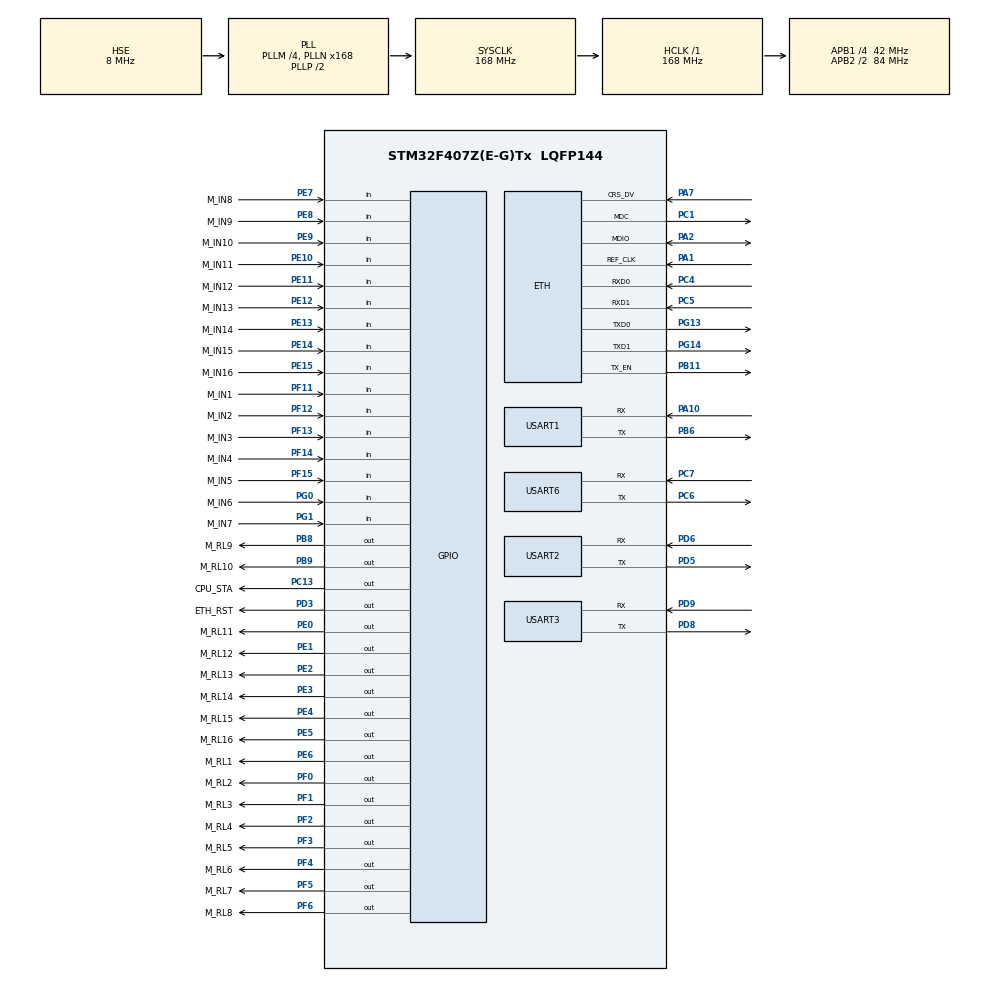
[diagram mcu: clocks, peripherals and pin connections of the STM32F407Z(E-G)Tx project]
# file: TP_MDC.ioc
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Dma.Request0=USART1_RX
Dma.Request1=USART1_TX
Dma.Request2=USART2_RX
Dma.Request3=USART2_TX
Dma.Request4=USART3_RX
Dma.Request5=USART3_TX
Dma.Request6=USART6_RX
Dma.Request7=USART6_TX
Dma.USART1_RX.0.Direction=DMA_PERIPH_TO_MEMORY
Dma.USART1_RX.0.FIFOMode=DMA_FIFOMODE_DISABLE
Dma.USART1_RX.0.Instance=DMA2_Stream2
Dma.USART1_RX.0.MemDataAlignment=DMA_MDATAALIGN_BYTE
Dma.USART1_RX.0.MemInc=DMA_MINC_ENABLE
Dma.USART1_RX.0.Mode=DMA_CIRCULAR
Dma.USART1_RX.0.PeriphDataAlignment=DMA_PDATAALIGN_BYTE
Dma.USART1_RX.0.PeriphInc=DMA_PINC_DISABLE
Dma.USART1_RX.0.Priority=DMA_PRIORITY_LOW
Dma.USART1_TX.1.Direction=DMA_MEMORY_TO_PERIPH
Dma.USART1_TX.1.FIFOMode=DMA_FIFOMODE_DISABLE
Dma.USART1_TX.1.Instance=DMA2_Stream7
Dma.USART1_TX.1.MemDataAlignment=DMA_MDATAALIGN_BYTE
Dma.USART1_TX.1.MemInc=DMA_MINC_ENABLE
Dma.USART1_TX.1.Mode=DMA_NORMAL
Dma.USART1_TX.1.PeriphDataAlignment=DMA_PDATAALIGN_BYTE
Dma.USART1_TX.1.PeriphInc=DMA_PINC_DISABLE
Dma.USART1_TX.1.Priority=DMA_PRIORITY_LOW
Dma.USART2_RX.2.Direction=DMA_PERIPH_TO_MEMORY
Dma.USART2_RX.2.FIFOMode=DMA_FIFOMODE_DISABLE
Dma.USART2_RX.2.Instance=DMA1_Stream5
Dma.USART2_RX.2.MemDataAlignment=DMA_MDATAALIGN_BYTE
Dma.USART2_RX.2.MemInc=DMA_MINC_ENABLE
Dma.USART2_RX.2.Mode=DMA_CIRCULAR
Dma.USART2_RX.2.PeriphDataAlignment=DMA_PDATAALIGN_BYTE
Dma.USART2_RX.2.PeriphInc=DMA_PINC_DISABLE
Dma.USART2_RX.2.Priority=DMA_PRIORITY_LOW
Dma.USART2_TX.3.Direction=DMA_MEMORY_TO_PERIPH
Dma.USART2_TX.3.FIFOMode=DMA_FIFOMODE_DISABLE
Dma.USART2_TX.3.Instance=DMA1_Stream6
Dma.USART2_TX.3.MemDataAlignment=DMA_MDATAALIGN_BYTE
Dma.USART2_TX.3.MemInc=DMA_MINC_ENABLE
Dma.USART2_TX.3.Mode=DMA_NORMAL
Dma.USART2_TX.3.PeriphDataAlignment=DMA_PDATAALIGN_BYTE
Dma.USART2_TX.3.PeriphInc=DMA_PINC_DISABLE
Dma.USART2_TX.3.Priority=DMA_PRIORITY_LOW
Dma.USART3_RX.4.Direction=DMA_PERIPH_TO_MEMORY
Dma.USART3_RX.4.FIFOMode=DMA_FIFOMODE_DISABLE
Dma.USART3_RX.4.Instance=DMA1_Stream1
Dma.USART3_RX.4.MemDataAlignment=DMA_MDATAALIGN_BYTE
Dma.USART3_RX.4.MemInc=DMA_MINC_ENABLE
Dma.USART3_RX.4.Mode=DMA_CIRCULAR
Dma.USART3_RX.4.PeriphDataAlignment=DMA_PDATAALIGN_BYTE
Dma.USART3_RX.4.PeriphInc=DMA_PINC_DISABLE
Dma.USART3_RX.4.Priority=DMA_PRIORITY_LOW
Dma.USART3_TX.5.Direction=DMA_MEMORY_TO_PERIPH
Dma.USART3_TX.5.FIFOMode=DMA_FIFOMODE_DISABLE
Dma.USART3_TX.5.Instance=DMA1_Stream3
Dma.USART3_TX.5.MemDataAlignment=DMA_MDATAALIGN_BYTE
Dma.USART3_TX.5.MemInc=DMA_MINC_ENABLE
Dma.USART3_TX.5.Mode=DMA_NORMAL
Dma.USART3_TX.5.PeriphDataAlignment=DMA_PDATAALIGN_BYTE
Dma.USART3_TX.5.PeriphInc=DMA_PINC_DISABLE
Dma.USART3_TX.5.Priority=DMA_PRIORITY_LOW
Dma.USART6_RX.6.Direction=DMA_PERIPH_TO_MEMORY
Dma.USART6_RX.6.FIFOMode=DMA_FIFOMODE_DISABLE
Dma.USART6_RX.6.Instance=DMA2_Stream1
Dma.USART6_RX.6.MemDataAlignment=DMA_MDATAALIGN_BYTE
Dma.USART6_RX.6.MemInc=DMA_MINC_ENABLE
Dma.USART6_RX.6.Mode=DMA_CIRCULAR
Dma.USART6_RX.6.PeriphDataAlignment=DMA_PDATAALIGN_BYTE
Dma.USART6_RX.6.PeriphInc=DMA_PINC_DISABLE
Dma.USART6_RX.6.Priority=DMA_PRIORITY_LOW
Dma.USART6_TX.7.Direction=DMA_MEMORY_TO_PERIPH
Dma.USART6_TX.7.FIFOMode=DMA_FIFOMODE_DISABLE
Dma.USART6_TX.7.Instance=DMA2_Stream6
Dma.USART6_TX.7.MemDataAlignment=DMA_MDATAALIGN_BYTE
Dma.USART6_TX.7.MemInc=DMA_MINC_ENABLE
Dma.USART6_TX.7.Mode=DMA_NORMAL
Dma.USART6_TX.7.PeriphDataAlignment=DMA_PDATAALIGN_BYTE
Dma.USART6_TX.7.PeriphInc=DMA_PINC_DISABLE
Dma.USART6_TX.7.Priority=DMA_PRIORITY_LOW
ETH.MediaInterface=HAL_ETH_RMII_MODE
FREERTOS.Tasks01=defaultTask,24,512,StartDefaultTask,Default,NULL,Dynamic,NULL,NULL
FREERTOS.configTOTAL_HEAP_SIZE=49152
LWIP.BSP.number=1
LWIP.IP_ADDRESS=192.168.031.100
LWIP.LWIP_DHCP=0
LWIP.NETMASK_ADDRESS=255.255.255.000
LWIP.Version=v2.1.2_Cube
LWIP0.BSP.STBoard=false
LWIP0.BSP.api=BSP_COMPONENT_DRIVER
LWIP0.BSP.component=LAN8742
LWIP0.BSP.instance=LAN8742
LWIP0.BSP.name=Driver_PHY
LWIP0.BSP.semaphore=S_LAN8742
LWIP0.BSP.solution=LAN8742
Mcu.Family=STM32F4
Mcu.Name=STM32F407Z(E-G)Tx
Mcu.Package=LQFP144
NVIC.DMA1_Stream1_IRQn=true\:5\:0\:false\:false\:true\:true\:false\:true\:true
NVIC.DMA1_Stream3_IRQn=true\:5\:0\:false\:false\:true\:true\:false\:true\:true
NVIC.DMA1_Stream5_IRQn=true\:5\:0\:false\:false\:true\:true\:false\:true\:true
NVIC.DMA1_Stream6_IRQn=true\:5\:0\:false\:false\:true\:true\:false\:true\:true
NVIC.DMA2_Stream1_IRQn=true\:5\:0\:false\:false\:true\:true\:false\:true\:true
NVIC.DMA2_Stream2_IRQn=true\:5\:0\:false\:false\:true\:true\:false\:true\:true
NVIC.DMA2_Stream6_IRQn=true\:5\:0\:false\:false\:true\:true\:false\:true\:true
NVIC.DMA2_Stream7_IRQn=true\:5\:0\:false\:false\:true\:true\:false\:true\:true
NVIC.ETH_IRQn=true\:5\:0\:false\:false\:true\:true\:false\:true\:true
NVIC.PriorityGroup=NVIC_PRIORITYGROUP_4
NVIC.TIM2_IRQn=true\:15\:0\:true\:false\:true\:false\:false\:true\:true
NVIC.TimeBase=TIM2_IRQn
NVIC.TimeBaseIP=TIM2
NVIC.USART1_IRQn=true\:5\:0\:false\:false\:true\:true\:true\:true\:true
NVIC.USART2_IRQn=true\:5\:0\:false\:false\:true\:true\:true\:true\:true
NVIC.USART3_IRQn=true\:5\:0\:false\:false\:true\:true\:true\:true\:true
NVIC.USART6_IRQn=true\:5\:0\:false\:false\:true\:true\:true\:true\:true
PA1.Mode=RMII
PA1.Signal=ETH_REF_CLK
PA10.Mode=Asynchronous
PA10.Signal=USART1_RX
PA13.Mode=Serial_Wire
PA13.Signal=SYS_JTMS-SWDIO
PA14.Mode=Serial_Wire
PA14.Signal=SYS_JTCK-SWCLK
PA2.Mode=RMII
PA2.Signal=ETH_MDIO
PA7.Mode=RMII
PA7.Signal=ETH_CRS_DV
PB11.Mode=RMII
PB11.Signal=ETH_TX_EN
PB6.Mode=Asynchronous
PB6.Signal=USART1_TX
PB8.GPIO_Label=M_RL9
PB8.GPIO_PuPd=GPIO_PULLDOWN
PB8.GPIO_Speed=GPIO_SPEED_FREQ_MEDIUM
PB8.PinState=GPIO_PIN_RESET
PB8.Signal=GPIO_Output
PB9.GPIO_Label=M_RL10
PB9.GPIO_PuPd=GPIO_PULLDOWN
PB9.GPIO_Speed=GPIO_SPEED_FREQ_MEDIUM
PB9.Signal=GPIO_Output
PC1.Mode=RMII
PC1.Signal=ETH_MDC
PC13-ANTI_TAMP.GPIO_Label=CPU_STA
PC13-ANTI_TAMP.Signal=GPIO_Output
PC14-OSC32_IN.Mode=LSE-External-Oscillator
PC14-OSC32_IN.Signal=RCC_OSC32_IN
PC15-OSC32_OUT.Mode=LSE-External-Oscillator
PC15-OSC32_OUT.Signal=RCC_OSC32_OUT
PC4.Mode=RMII
PC4.Signal=ETH_RXD0
PC5.Mode=RMII
PC5.Signal=ETH_RXD1
PC6.Mode=Asynchronous
PC6.Signal=USART6_TX
PC7.Mode=Asynchronous
PC7.Signal=USART6_RX
PD3.GPIO_Label=ETH_RST
PD3.Signal=GPIO_Output
PD5.Mode=Asynchronous
PD5.Signal=USART2_TX
PD6.Mode=Asynchronous
PD6.Signal=USART2_RX
PD8.Mode=Asynchronous
PD8.Signal=USART3_TX
PD9.Mode=Asynchronous
PD9.Signal=USART3_RX
PE0.GPIO_Label=M_RL11
PE0.GPIO_PuPd=GPIO_PULLDOWN
PE0.GPIO_Speed=GPIO_SPEED_FREQ_MEDIUM
PE0.Signal=GPIO_Output
PE1.GPIO_Label=M_RL12
PE1.GPIO_PuPd=GPIO_PULLDOWN
PE1.GPIO_Speed=GPIO_SPEED_FREQ_MEDIUM
PE1.Signal=GPIO_Output
PE10.GPIO_Label=M_IN11
PE10.GPIO_PuPd=GPIO_PULLUP
PE10.Signal=GPIO_Input
PE11.GPIO_Label=M_IN12
PE11.GPIO_PuPd=GPIO_PULLUP
PE11.Signal=GPIO_Input
PE12.GPIO_Label=M_IN13
PE12.GPIO_PuPd=GPIO_PULLUP
PE12.Signal=GPIO_Input
PE13.GPIO_Label=M_IN14
PE13.GPIO_PuPd=GPIO_PULLUP
PE13.Signal=GPIO_Input
PE14.GPIO_Label=M_IN15
PE14.GPIO_PuPd=GPIO_PULLUP
PE14.Signal=GPIO_Input
PE15.GPIO_Label=M_IN16
PE15.GPIO_PuPd=GPIO_PULLUP
PE15.Signal=GPIO_Input
PE2.GPIO_Label=M_RL13
PE2.GPIO_PuPd=GPIO_PULLDOWN
PE2.GPIO_Speed=GPIO_SPEED_FREQ_MEDIUM
PE2.Signal=GPIO_Output
PE3.GPIO_Label=M_RL14
PE3.GPIO_PuPd=GPIO_PULLDOWN
PE3.GPIO_Speed=GPIO_SPEED_FREQ_MEDIUM
PE3.Signal=GPIO_Output
PE4.GPIO_Label=M_RL15
PE4.GPIO_PuPd=GPIO_PULLDOWN
PE4.GPIO_Speed=GPIO_SPEED_FREQ_MEDIUM
PE4.Signal=GPIO_Output
PE5.GPIO_Label=M_RL16
PE5.GPIO_PuPd=GPIO_PULLDOWN
PE5.GPIO_Speed=GPIO_SPEED_FREQ_MEDIUM
PE5.Signal=GPIO_Output
PE6.GPIO_Label=M_RL1
PE6.GPIO_PuPd=GPIO_PULLDOWN
PE6.GPIO_Speed=GPIO_SPEED_FREQ_MEDIUM
PE6.Signal=GPIO_Output
PE7.GPIO_Label=M_IN8
PE7.GPIO_PuPd=GPIO_PULLUP
PE7.Signal=GPIO_Input
PE8.GPIO_Label=M_IN9
PE8.GPIO_PuPd=GPIO_PULLUP
PE8.Signal=GPIO_Input
PE9.GPIO_Label=M_IN10
PE9.GPIO_PuPd=GPIO_PULLUP
PE9.Signal=GPIO_Input
PF0.GPIO_Label=M_RL2
PF0.GPIO_PuPd=GPIO_PULLDOWN
PF0.GPIO_Speed=GPIO_SPEED_FREQ_MEDIUM
PF0.Signal=GPIO_Output
PF1.GPIO_Label=M_RL3
PF1.GPIO_PuPd=GPIO_PULLDOWN
PF1.GPIO_Speed=GPIO_SPEED_FREQ_MEDIUM
PF1.Signal=GPIO_Output
PF11.GPIO_Label=M_IN1
PF11.GPIO_PuPd=GPIO_PULLUP
PF11.Signal=GPIO_Input
PF12.GPIO_Label=M_IN2
PF12.GPIO_PuPd=GPIO_PULLUP
PF12.Signal=GPIO_Input
PF13.GPIO_Label=M_IN3
PF13.GPIO_PuPd=GPIO_PULLUP
PF13.Signal=GPIO_Input
PF14.GPIO_Label=M_IN4
PF14.GPIO_PuPd=GPIO_PULLUP
PF14.Signal=GPIO_Input
PF15.GPIO_Label=M_IN5
PF15.GPIO_PuPd=GPIO_PULLUP
PF15.Signal=GPIO_Input
PF2.GPIO_Label=M_RL4
PF2.GPIO_PuPd=GPIO_PULLDOWN
PF2.GPIO_Speed=GPIO_SPEED_FREQ_MEDIUM
PF2.Signal=GPIO_Output
PF3.GPIO_Label=M_RL5
PF3.GPIO_PuPd=GPIO_PULLDOWN
PF3.GPIO_Speed=GPIO_SPEED_FREQ_MEDIUM
PF3.Signal=GPIO_Output
PF4.GPIO_Label=M_RL6
PF4.GPIO_PuPd=GPIO_PULLDOWN
PF4.GPIO_Speed=GPIO_SPEED_FREQ_MEDIUM
PF4.Signal=GPIO_Output
PF5.GPIO_Label=M_RL7
PF5.GPIO_PuPd=GPIO_PULLDOWN
PF5.GPIO_Speed=GPIO_SPEED_FREQ_MEDIUM
PF5.Signal=GPIO_Output
PF6.GPIO_Label=M_RL8
PF6.GPIO_PuPd=GPIO_PULLDOWN
PF6.GPIO_Speed=GPIO_SPEED_FREQ_MEDIUM
PF6.Signal=GPIO_Output
PG0.GPIO_Label=M_IN6
PG0.GPIO_PuPd=GPIO_PULLUP
PG0.Signal=GPIO_Input
PG1.GPIO_Label=M_IN7
PG1.GPIO_PuPd=GPIO_PULLUP
PG1.Signal=GPIO_Input
PG13.Mode=RMII
PG13.Signal=ETH_TXD0
PG14.Mode=RMII
PG14.Signal=ETH_TXD1
PH0-OSC_IN.Mode=HSE-External-Oscillator
PH0-OSC_IN.Signal=RCC_OSC_IN
PH1-OSC_OUT.Mode=HSE-External-Oscillator
PH1-OSC_OUT.Signal=RCC_OSC_OUT
ProjectManager.HeapSize=0x2000
ProjectManager.StackSize=0x2000
ProjectManager.TargetToolchain=CMake
RCC.48MHZClocksFreq_Value=48000000
RCC.AHBFreq_Value=168000000
RCC.APB1CLKDivider=RCC_HCLK_DIV4
RCC.APB1Freq_Value=42000000
RCC.APB1TimFreq_Value=84000000
RCC.APB2CLKDivider=RCC_HCLK_DIV2
RCC.APB2Freq_Value=84000000
RCC.APB2TimFreq_Value=168000000
RCC.CortexFreq_Value=168000000
RCC.HCLKFreq_Value=168000000
RCC.HSE_VALUE=8000000
RCC.HSI_VALUE=16000000
RCC.PLLM=4
RCC.PLLN=168
RCC.PLLQ=7
RCC.PLLSourceVirtual=RCC_PLLSOURCE_HSE
RCC.SYSCLKFreq_VALUE=168000000
RCC.SYSCLKSource=RCC_SYSCLKSOURCE_PLLCLK
RCC.VCOOutputFreq_Value=336000000
USART1.VirtualMode=VM_ASYNC
USART2.VirtualMode=VM_ASYNC
USART3.VirtualMode=VM_ASYNC
USART6.VirtualMode=VM_ASYNC
VP_FREERTOS_VS_CMSIS_V2.Mode=CMSIS_V2
VP_IWDG_VS_IWDG.Mode=IWDG_Activate
VP_LWIP_VS_Enabled.Mode=Enabled
VP_SYS_VS_tim2.Mode=TIM2
board=custom

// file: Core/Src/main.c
/* USER CODE BEGIN Header */
/**
  ******************************************************************************
  * @file           : main.c
  * @brief          : Main program body
  ******************************************************************************
  * @attention
  *
  * Copyright (c) 2026 STMicroelectronics.
  * All rights reserved.
  *
  * This software is licensed under terms that can be found in the LICENSE file
  * in the root directory of this software component.
  * If no LICENSE file comes with this software, it is provided AS-IS.
  *
  ******************************************************************************
  */
/* USER CODE END Header */
#include "main.h"
#include "cmsis_os.h"
#include "dma.h"
#include "lwip.h"
#include "usart.h"
#include "gpio.h"

/* USER CODE BEGIN Includes */
#include "app_main.h"
/* USER CODE END Includes */

void SystemClock_Config(void);
void MX_FREERTOS_Init(void);

int main(void)
{

  /* MCU Configuration--------------------------------------------------------*/

  /* Reset of all peripherals, Initializes the Flash interface and the Systick. */
  HAL_Init();

  /* Configure the system clock */
  SystemClock_Config();

  /* Initialize all configured peripherals */
  MX_GPIO_Init();
  MX_DMA_Init();
  MX_USART1_UART_Init();
  MX_USART2_UART_Init();
  MX_USART3_UART_Init();
  MX_USART6_UART_Init();
  /* USER CODE BEGIN 2 */
  // App_Init();
  /* USER CODE END 2 */

  /* Init scheduler */
  osKernelInitialize();  /* Call init function for freertos objects (in cmsis_os2.c) */
  MX_FREERTOS_Init();

  /* Start scheduler */
  osKernelStart();

  /* We should never get here as control is now taken by the scheduler */

  /* Infinite loop */
  while (1)
  {

  }
}

void SystemClock_Config(void)
{
  RCC_OscInitTypeDef RCC_OscInitStruct = {0};
  RCC_ClkInitTypeDef RCC_ClkInitStruct = {0};

  /** Configure the main internal regulator output voltage
  */
  __HAL_RCC_PWR_CLK_ENABLE();
  __HAL_PWR_VOLTAGESCALING_CONFIG(PWR_REGULATOR_VOLTAGE_SCALE1);

  /** Initializes the RCC Oscillators according to the specified parameters
  * in the RCC_OscInitTypeDef structure.
  */
  RCC_OscInitStruct.OscillatorType = RCC_OSCILLATORTYPE_LSI|RCC_OSCILLATORTYPE_HSE;
  RCC_OscInitStruct.HSEState = RCC_HSE_ON;
  RCC_OscInitStruct.LSIState = RCC_LSI_ON;
  RCC_OscInitStruct.PLL.PLLState = RCC_PLL_ON;
  RCC_OscInitStruct.PLL.PLLSource = RCC_PLLSOURCE_HSE;
  RCC_OscInitStruct.PLL.PLLM = 4;
  RCC_OscInitStruct.PLL.PLLN = 168;
  RCC_OscInitStruct.PLL.PLLP = RCC_PLLP_DIV2;
  RCC_OscInitStruct.PLL.PLLQ = 7;
  if (HAL_RCC_OscConfig(&RCC_OscInitStruct) != HAL_OK)
  {
    Error_Handler();
  }

  /** Initializes the CPU, AHB and APB buses clocks
  */
  RCC_ClkInitStruct.ClockType = RCC_CLOCKTYPE_HCLK|RCC_CLOCKTYPE_SYSCLK
                              |RCC_CLOCKTYPE_PCLK1|RCC_CLOCKTYPE_PCLK2;
  RCC_ClkInitStruct.SYSCLKSource = RCC_SYSCLKSOURCE_PLLCLK;
  RCC_ClkInitStruct.AHBCLKDivider = RCC_SYSCLK_DIV1;
  RCC_ClkInitStruct.APB1CLKDivider = RCC_HCLK_DIV4;
  RCC_ClkInitStruct.APB2CLKDivider = RCC_HCLK_DIV2;

  if (HAL_RCC_ClockConfig(&RCC_ClkInitStruct, FLASH_LATENCY_5) != HAL_OK)
  {
    Error_Handler();
  }
}

void HAL_TIM_PeriodElapsedCallback(TIM_HandleTypeDef *htim)
{
  if (htim->Instance == TIM2)
  {
    HAL_IncTick();
  }
}

void Error_Handler(void)
{
  __disable_irq();
  while (1)
  {
  }
}

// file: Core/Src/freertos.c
/* USER CODE BEGIN Header */
/**
  ******************************************************************************
  * File Name          : freertos.c
  * Description        : Code for freertos applications
  ******************************************************************************
  * @attention
  *
  * Copyright (c) 2026 STMicroelectronics.
  * All rights reserved.
  *
  * This software is licensed under terms that can be found in the LICENSE file
  * in the root directory of this software component.
  * If no LICENSE file comes with this software, it is provided AS-IS.
  *
  ******************************************************************************
  */
/* USER CODE END Header */

#include "FreeRTOS.h"
#include "task.h"
#include "main.h"
#include "cmsis_os.h"

/* USER CODE BEGIN Includes */
#include "app_main.h"
/* USER CODE END Includes */

/* Definitions for defaultTask */
osThreadId_t defaultTaskHandle;
const osThreadAttr_t defaultTask_attributes = {
  .name = "defaultTask",
  .stack_size = 512 * 4,
  .priority = (osPriority_t) osPriorityNormal,
};

void StartDefaultTask(void *argument);

extern void MX_LWIP_Init(void);
void MX_FREERTOS_Init(void); /* (MISRA C 2004 rule 8.1) */

void MX_FREERTOS_Init(void) {
  /* USER CODE BEGIN Init */
  App_Init();
  /* USER CODE END Init */

  /* Create the thread(s) */
  /* creation of defaultTask */
  defaultTaskHandle = osThreadNew(StartDefaultTask, NULL, &defaultTask_attributes);

}

void StartDefaultTask(void *argument)
{
  /* init code for LWIP */
  MX_LWIP_Init();
  for(;;)
  {
    osDelay(1);
  }
}
